VERSION ""

NS_ :

BS_:

BU_: MARVEL_3WL5_CAN_V0_3

BO_ 3221225472 VECTOR__INDEPENDENT_SIG_MSG: 0 Vector__XXX
 SG_ packVoltage_2949 : 0|8@0- (0.1,0) [0|0] "V" Vector__XXX
 SG_ pIn_OCD_WarningCurrent : 0|16@1+ (1,0) [0|0] "A" Vector__XXX
 SG_ pIn_OCD_ErrorCurrent : 0|16@1+ (1,0) [0|0] "A" Vector__XXX
 SG_ pIn_OTC_WarningTimeout : 0|16@1+ (1,0) [0|0] "ms" Vector__XXX
 SG_ pIn_OTC_ErrorTimeout : 0|16@1+ (1,0) [0|0] "ms" Vector__XXX
 SG_ pIn_OTC_RecoveryTimeout : 0|16@1+ (1,0) [0|0] "ms" Vector__XXX
 SG_ pIn_OTC_WarningTemperature : 0|8@1+ (1,0) [0|0] "C" Vector__XXX
 SG_ pIn_OTC_ErrorTemperature : 0|8@1+ (1,0) [0|0] "C" Vector__XXX
 SG_ pIn_OTC_RecoveryTemperature : 0|8@1+ (1,0) [0|0] "C" Vector__XXX
 SG_ pIn_OTD_WarningTemperature : 0|8@1+ (1,0) [0|0] "C" Vector__XXX
 SG_ pIn_OTD_ErrorTemperature : 0|8@1+ (1,0) [0|0] "C" Vector__XXX
 SG_ pIn_OTD_RecoveryTemperature : 0|8@1+ (1,0) [0|0] "C" Vector__XXX
 SG_ pIn_UTC_WarningTemperature : 0|8@1+ (1,0) [0|0] "C" Vector__XXX
 SG_ pIn_UTC_ErrorTemperature : 0|8@1+ (1,0) [0|0] "C" Vector__XXX
 SG_ pIn_UTC_RecoveryTemperature : 0|8@1+ (1,0) [0|0] "C" Vector__XXX
 SG_ pIn_UTD_WarningTemperature : 0|8@1+ (1,0) [0|0] "C" Vector__XXX
 SG_ pIn_UTD_ErrorTemperature : 0|8@1+ (1,0) [0|0] "C" Vector__XXX
 SG_ pIn_UTD_RecoveryTemperature : 0|8@1+ (1,0) [0|0] "C" Vector__XXX
 SG_ pIn_OV_RecoveryVoltage : 0|16@1+ (0.1,0) [0|0] "mV" Vector__XXX
 SG_ pIn_OV_ErrorVoltage : 0|16@1+ (0.1,0) [0|0] "mV" Vector__XXX
 SG_ pIn_OV_WarningVoltage : 0|16@1+ (0.1,0) [0|0] "mV" Vector__XXX
 SG_ pIn_UV_RecoveryVoltage : 0|16@1+ (0.1,0) [0|0] "mV" Vector__XXX
 SG_ pIn_UV_ErrorVoltage : 0|16@1+ (0.1,0) [0|0] "mV" Vector__XXX
 SG_ pIn_UV_WarningVoltage : 0|16@1+ (0.1,0) [0|0] "mV" Vector__XXX
 SG_ cbIn_BalMinThreshold : 0|16@1+ (0.1,0) [0|0] "mV" Vector__XXX
 SG_ cbIn_BalMaxAllowed_Imbalance : 0|16@1+ (0.1,0) [0|0] "mV" Vector__XXX
 SG_ cbIn_BalOVProtect_Threshold : 0|16@1+ (0.1,0) [0|0] "mV" Vector__XXX
 SG_ cbIn_BalStateRestPeriod : 0|16@1+ (1,0) [0|0] "ms" Vector__XXX
 SG_ Max_Allowed_Cell_Voltage : 0|16@1+ (1,0) [0|4150] "mV" Vector__XXX
 SG_ Max_Allowed_Pack_Voltage : 0|16@1+ (1,0) [0|83] "V" Vector__XXX
 SG_ Max_Allowed_Cell_Temperature : 0|16@1+ (1,0) [0|50] "C" Vector__XXX
 SG_ Max_Allowed_Current : 0|16@1+ (1,0) [0|200] "A" Vector__XXX
 SG_ Derated_Charge_Current : 0|16@1+ (0.1,0) [0|655.35] "A" Vector__XXX
 SG_ ccm_occ2Reg : 0|8@1+ (1,0) [0|0] "" Vector__XXX
 SG_ ccm_occ1Reg : 0|8@1+ (1,0) [0|0] "" Vector__XXX
 SG_ ccIn_VehicleRest_Time : 0|16@1+ (1,0) [0|0] "s" Vector__XXX
 SG_ ccIn_Max_CellCapacity : 0|16@1+ (1,0) [0|0] "Ah" Vector__XXX
 SG_ ccOut_Terminal_Voltage : 0|16@1+ (0.1,0) [0|0] "mV" Vector__XXX
 SG_ ccOut_EKF_Voltage : 0|16@1+ (0.1,0) [0|0] "mV" Vector__XXX
 SG_ ccOut_EKF_Capacity : 0|32@1- (1,0) [-2147483648|2147483647] "mAh" Vector__XXX
 SG_ ccOut_EKF_SOC_Pct : 0|8@1+ (1,0) [0|0] "" Vector__XXX
 SG_ Charging_State : 0|8@0+ (1,0) [0|1] "" Vector__XXX
 SG_ Charging_Current : 0|16@0+ (0.1,0) [0|180] "A" Vector__XXX
 SG_ Charging_Voltage : 0|16@0+ (0.1,0) [0|100] "V" Vector__XXX
 SG_ cIn_pOut_UTD : 0|8@1+ (1,0) [0|0] "" Vector__XXX
 SG_ cIn_pOut_UTC : 0|8@1+ (1,0) [0|0] "" Vector__XXX
 SG_ cIn_pOut_OTD : 0|8@1+ (1,0) [0|0] "" Vector__XXX
 SG_ cIn_pOut_OTC : 0|8@1+ (1,0) [0|0] "" Vector__XXX
 SG_ ErrorTypeGroup5 : 0|8@1- (1,0) [0|0] "" Vector__XXX
 SG_ ErrorTypeGroup4 : 0|8@1- (1,0) [0|0] "" Vector__XXX
 SG_ ErrorTypeGroup3 : 0|8@1- (1,0) [0|0] "" Vector__XXX
 SG_ TempGroup5 : 0|8@1- (1,0) [0|0] "" Vector__XXX
 SG_ TempGroup4 : 0|8@1- (1,0) [0|0] "" Vector__XXX
 SG_ TempGroup3 : 0|8@1- (1,0) [0|0] "" Vector__XXX
 SG_ pIn_Temp_20 : 0|8@1+ (1,0) [0|0] "C" Vector__XXX
 SG_ pIn_Temp_19 : 0|8@1+ (1,0) [0|0] "C" Vector__XXX
 SG_ pIn_Temp_18 : 0|8@1+ (1,0) [0|0] "C" Vector__XXX
 SG_ pIn_Temp_17 : 0|8@1+ (1,0) [0|0] "C" Vector__XXX
 SG_ pIn_Temp_16 : 0|8@1+ (1,0) [0|0] "C" Vector__XXX
 SG_ pIn_Temp_15 : 0|8@1+ (1,0) [0|0] "C" Vector__XXX
 SG_ Total_Cap_Remaining : 0|32@1- (1,0) [-2147483648|2147483647] "mAh" Vector__XXX
 SG_ Total_Cap_Charg_Discharge : 0|32@1- (1,0) [-2147483648|2147483647] "mAh" Vector__XXX
 SG_ Initial_Capacity : 0|32@1- (1,0) [-2147483648|2147483647] "mAh" Vector__XXX
 SG_ ccOut_CC_State : 0|8@1+ (1,0) [0|0] "" Vector__XXX
 SG_ ccOut_CC_SOC_Pct : 0|8@1+ (1,0) [0|0] "" Vector__XXX
 SG_ ccIn_Rest_Current : 0|8@1- (1,0) [0|0] "A" Vector__XXX
 SG_ ccIn_Voltage : 0|16@1+ (0.1,0) [0|0] "mV" Vector__XXX
 SG_ ccIn_pOut_OVThreshold : 0|8@1+ (1,0) [0|0] "" Vector__XXX
 SG_ ccIn_Current : 0|32@1- (0.01,0) [-1000|1000] "mA" Vector__XXX
 SG_ pIn_Temp_14 : 0|8@1+ (1,0) [0|0] "C" Vector__XXX
 SG_ CMU2_Cell_Voltage_12 : 0|16@1+ (0.1,0) [3100|4200] "mV" Vector__XXX
 SG_ CMU2_Cell_Voltage_11 : 0|16@1+ (0.1,0) [3100|4200] "mV" Vector__XXX
 SG_ CMU2_Cell_Voltage_10 : 0|16@1+ (0.1,0) [3100|4200] "mV" Vector__XXX
 SG_ CMU1_Cell_Voltage_12 : 0|16@1+ (0.1,0) [3100|4200] "mV" Vector__XXX
 SG_ CMU1_Cell_Voltage_11 : 0|16@1+ (0.1,0) [3100|4200] "mV" Vector__XXX
 SG_ CMU1_Cell_Voltage_10 : 0|16@1+ (0.1,0) [3100|4200] "mV" Vector__XXX
 SG_ errorDetect : 0|8@1- (1,0) [0|0] "" Vector__XXX
 SG_ eFuseFlag : 0|8@1- (1,0) [0|0] "" Vector__XXX
 SG_ dynamicCurrentState : 0|8@1- (1,0) [0|0] "" Vector__XXX
 SG_ errorDetect : 0|8@1- (1,0) [0|0] "" Vector__XXX

BO_ 831 calculatedFuseValue: 8 Vector__XXX
 SG_ i2t_Calculated_A2sec : 0|32@1- (1,0) [0|0] "" Vector__XXX

BO_ 263 ChargerID: 8 Vector__XXX
 SG_ ChargerCurrent : 23|16@0+ (0.1,0) [0|0] "Amps" Vector__XXX
 SG_ ChargerVoltage : 7|16@0+ (0.1,0) [0|0] "" Vector__XXX

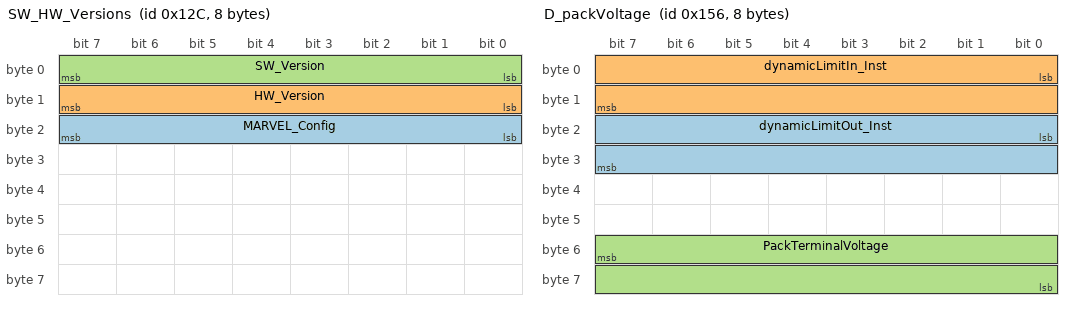
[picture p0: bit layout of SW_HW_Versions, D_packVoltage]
BO_ 300 SW_HW_Versions: 8 Vector__XXX
 SG_ MARVEL_Config : 16|8@1- (1,0) [0|0] "" Vector__XXX
 SG_ HW_Version : 8|8@1- (0.1,0) [0|0] "" Vector__XXX
 SG_ SW_Version : 0|8@1- (0.1,0) [0|0] "" Vector__XXX

BO_ 342 D_packVoltage: 8 Vector__XXX
 SG_ dynamicLimitOut_Inst : 16|16@1- (0.1,0) [0|0] "A" Vector__XXX
 SG_ dynamicLimitIn_Inst : 0|16@1- (0.1,0) [0|0] "" Vector__XXX
 SG_ PackTerminalVoltage : 55|16@0- (0.1,0) [0|0] "V" Vector__XXX

BO_ 801 AM_ccOutputs: 8 Vector__XXX
 SG_ TotalCapExchange : 32|32@1- (1,0) [0|0] "Ah" Vector__XXX
 SG_ MaxUsableCapacity : 0|32@1- (1,0) [0|0] "Ah" Vector__XXX

BO_ 829 DynamicCurrents: 8 Vector__XXX
 SG_ eFuseDischargingLimit_A2s : 32|32@1+ (1,0) [-1000000|1000000] "" Vector__XXX
 SG_ eFuseChargingLimit_A2s : 0|32@1+ (1,0) [-1000000|10000000] "" Vector__XXX

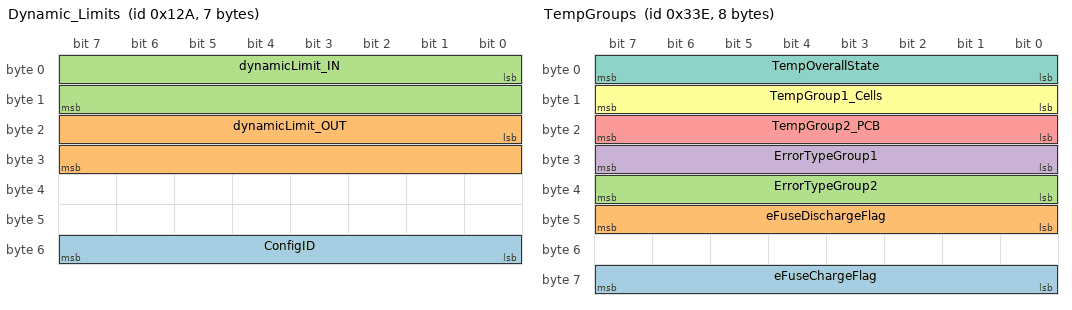
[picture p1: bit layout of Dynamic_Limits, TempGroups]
BO_ 298 Dynamic_Limits: 7 Vector__XXX
 SG_ ConfigID : 48|8@1- (1,0) [0|0] "" Vector__XXX
 SG_ dynamicLimit_OUT : 16|16@1- (0.1,0) [0|0] "A" Vector__XXX
 SG_ dynamicLimit_IN : 0|16@1- (0.1,0) [0|0] "A" Vector__XXX

BO_ 830 TempGroups: 8 Vector__XXX
 SG_ eFuseChargeFlag : 56|8@1- (1,0) [0|0] "" Vector__XXX
 SG_ eFuseDischargeFlag : 40|8@1- (1,0) [0|0] "" Vector__XXX
 SG_ ErrorTypeGroup2 : 32|8@1- (1,0) [0|0] "" Vector__XXX
 SG_ ErrorTypeGroup1 : 24|8@1- (1,0) [0|0] "" Vector__XXX
 SG_ TempGroup2_PCB : 16|8@1- (1,0) [0|0] "" Vector__XXX
 SG_ TempGroup1_Cells : 8|8@1- (1,0) [0|0] "" Vector__XXX
 SG_ TempOverallState : 0|8@1- (1,0) [0|0] "" Vector__XXX

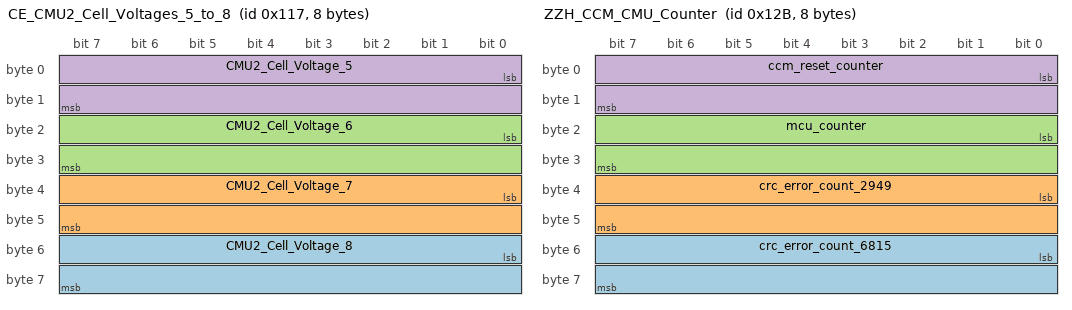
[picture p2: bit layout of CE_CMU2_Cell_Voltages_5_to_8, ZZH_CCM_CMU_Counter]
BO_ 279 CE_CMU2_Cell_Voltages_5_to_8: 8 Vector__XXX
 SG_ CMU2_Cell_Voltage_8 : 48|16@1+ (0.1,0) [3100|4200] "mV" Vector__XXX
 SG_ CMU2_Cell_Voltage_7 : 32|16@1+ (0.1,0) [3100|4200] "mV" Vector__XXX
 SG_ CMU2_Cell_Voltage_6 : 16|16@1+ (0.1,0) [3100|4200] "mV" Vector__XXX
 SG_ CMU2_Cell_Voltage_5 : 0|16@1+ (0.1,0) [3100|4200] "mV" Vector__XXX

BO_ 827 AL_ccOutput_Rem_Cap: 8 Vector__XXX
 SG_ TotalCapacityRemaining : 32|32@1- (1,0) [0|0] "mAh" Vector__XXX
 SG_ InitialCapacity : 0|32@1- (1,0) [0|0] "mAh" Vector__XXX

BO_ 299 ZZH_CCM_CMU_Counter: 8 Vector__XXX
 SG_ crc_error_count_6815 : 48|16@1+ (1,0) [0|0] "" Vector__XXX
 SG_ crc_error_count_2949 : 32|16@1+ (1,0) [0|0] "" Vector__XXX
 SG_ mcu_counter : 16|16@1+ (1,0) [0|0] "" Vector__XXX
 SG_ ccm_reset_counter : 0|16@1+ (1,0) [0|0] "" Vector__XXX

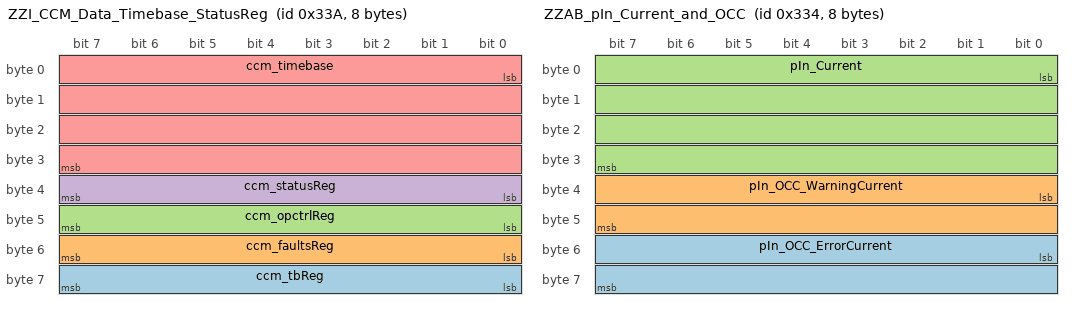
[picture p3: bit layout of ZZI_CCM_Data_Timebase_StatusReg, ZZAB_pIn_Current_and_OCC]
BO_ 826 ZZI_CCM_Data_Timebase_StatusReg: 8 Vector__XXX
 SG_ ccm_tbReg : 56|8@1+ (1,0) [0|0] "" Vector__XXX
 SG_ ccm_faultsReg : 48|8@1+ (1,0) [0|0] "" Vector__XXX
 SG_ ccm_opctrlReg : 40|8@1+ (1,0) [0|0] "" Vector__XXX
 SG_ ccm_statusReg : 32|8@1+ (1,0) [0|0] "" Vector__XXX
 SG_ ccm_timebase : 0|32@1+ (0.1,0) [0|429496729.5] "s" Vector__XXX

BO_ 820 ZZAB_pIn_Current_and_OCC: 8 Vector__XXX
 SG_ pIn_OCC_ErrorCurrent : 48|16@1+ (1,0) [0|0] "A" Vector__XXX
 SG_ pIn_OCC_WarningCurrent : 32|16@1+ (1,0) [0|0] "A" Vector__XXX
 SG_ pIn_Current : 0|32@1- (0.1,0) [-1000|1000] "mA" Vector__XXX

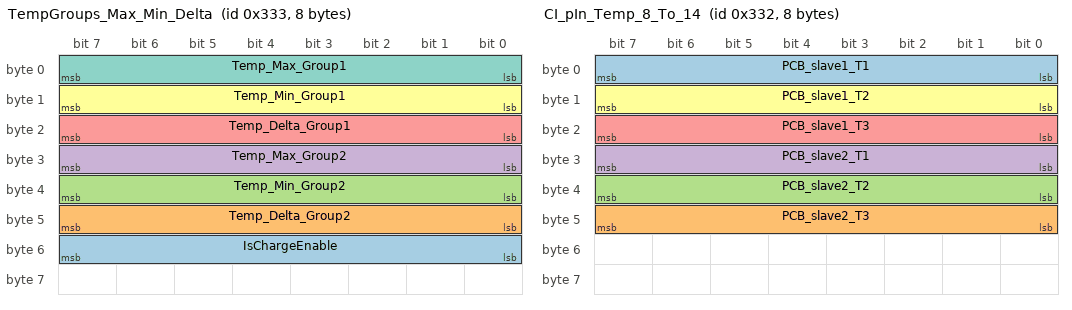
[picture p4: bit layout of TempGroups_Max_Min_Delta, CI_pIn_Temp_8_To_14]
BO_ 819 TempGroups_Max_Min_Delta: 8 Vector__XXX
 SG_ IsChargeEnable : 48|8@1+ (1,0) [0|0] "C" Vector__XXX
 SG_ Temp_Delta_Group2 : 40|8@1- (1,0) [0|0] "" Vector__XXX
 SG_ Temp_Min_Group2 : 32|8@1- (1,0) [0|0] "" Vector__XXX
 SG_ Temp_Max_Group2 : 24|8@1- (1,0) [0|0] "" Vector__XXX
 SG_ Temp_Delta_Group1 : 16|8@1+ (1,0) [0|0] "C" Vector__XXX
 SG_ Temp_Min_Group1 : 8|8@1+ (1,0) [0|0] "C" Vector__XXX
 SG_ Temp_Max_Group1 : 0|8@1+ (1,0) [0|0] "C" Vector__XXX

BO_ 818 CI_pIn_Temp_8_To_14: 8 Vector__XXX
 SG_ PCB_slave1_T1 : 0|8@1+ (1,0) [0|0] "C" Vector__XXX
 SG_ PCB_slave2_T3 : 40|8@1+ (1,0) [0|0] "C" Vector__XXX
 SG_ PCB_slave2_T2 : 32|8@1+ (1,0) [0|0] "C" Vector__XXX
 SG_ PCB_slave2_T1 : 24|8@1+ (1,0) [0|0] "C" Vector__XXX
 SG_ PCB_slave1_T3 : 16|8@1+ (1,0) [0|0] "C" Vector__XXX
 SG_ PCB_slave1_T2 : 8|8@1+ (1,0) [0|0] "C" Vector__XXX

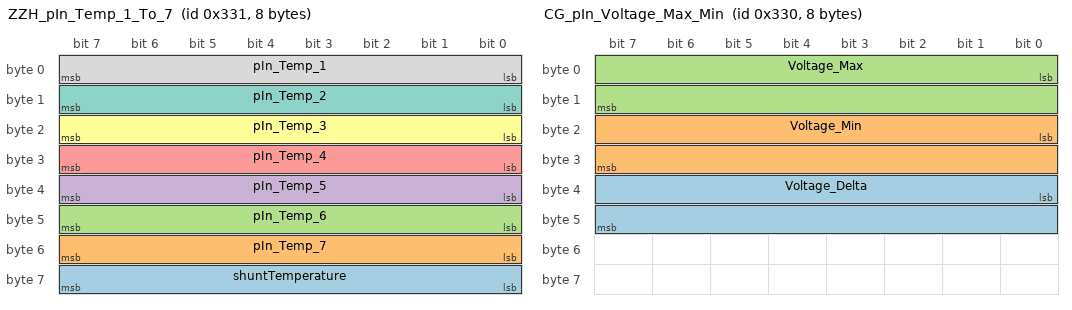
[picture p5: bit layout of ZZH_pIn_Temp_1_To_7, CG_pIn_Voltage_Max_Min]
BO_ 817 ZZH_pIn_Temp_1_To_7: 8 Vector__XXX
 SG_ shuntTemperature : 56|8@1- (1,0) [0|0] "deg" Vector__XXX
 SG_ pIn_Temp_7 : 48|8@1- (1,0) [0|0] "C" Vector__XXX
 SG_ pIn_Temp_6 : 40|8@1- (1,0) [0|0] "C" Vector__XXX
 SG_ pIn_Temp_5 : 32|8@1- (1,0) [0|0] "C" Vector__XXX
 SG_ pIn_Temp_4 : 24|8@1- (1,0) [0|0] "C" Vector__XXX
 SG_ pIn_Temp_3 : 16|8@1- (1,0) [0|0] "C" Vector__XXX
 SG_ pIn_Temp_2 : 8|8@1- (1,0) [0|0] "C" Vector__XXX
 SG_ pIn_Temp_1 : 0|8@1- (1,0) [0|0] "C" Vector__XXX

BO_ 816 CG_pIn_Voltage_Max_Min: 8 Vector__XXX
 SG_ Voltage_Delta : 32|16@1+ (0.1,0) [3100|4200] "mV" Vector__XXX
 SG_ Voltage_Min : 16|16@1+ (0.1,0) [3100|4200] "mV" Vector__XXX
 SG_ Voltage_Max : 0|16@1+ (0.1,0) [3100|4200] "mV" Vector__XXX

BO_ 280 CF_CMU2_Cell_Voltages_9_to_12: 8 Vector__XXX
 SG_ CMU2_Cell_Voltage_9 : 0|16@1+ (0.1,0) [3100|4200] "mV" Vector__XXX

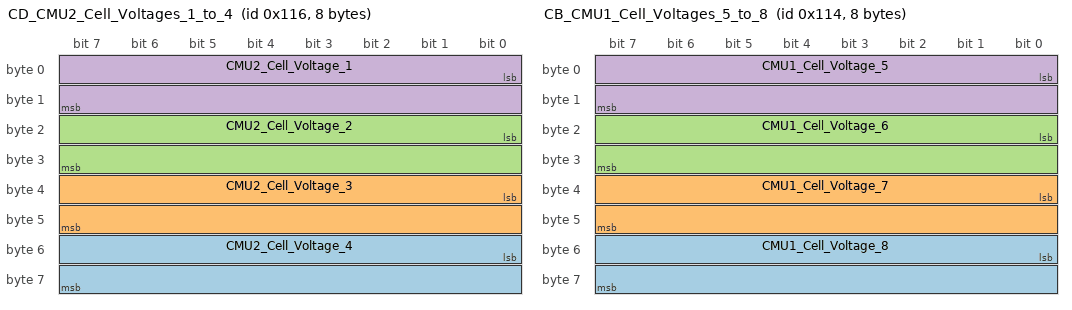
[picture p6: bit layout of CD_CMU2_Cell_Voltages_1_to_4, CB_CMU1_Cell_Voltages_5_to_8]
BO_ 278 CD_CMU2_Cell_Voltages_1_to_4: 8 Vector__XXX
 SG_ CMU2_Cell_Voltage_4 : 48|16@1+ (0.1,0) [3100|4200] "mV" Vector__XXX
 SG_ CMU2_Cell_Voltage_3 : 32|16@1+ (0.1,0) [3100|4200] "mV" Vector__XXX
 SG_ CMU2_Cell_Voltage_2 : 16|16@1+ (0.1,0) [3100|4200] "mV" Vector__XXX
 SG_ CMU2_Cell_Voltage_1 : 0|16@1+ (0.1,0) [3100|4200] "mV" Vector__XXX

BO_ 277 CC_CMU1_Cell_Voltages_9_to_12: 8 Vector__XXX
 SG_ CMU1_Cell_Voltage_9 : 0|16@1+ (0.1,0) [3100|4200] "mV" Vector__XXX

BO_ 276 CB_CMU1_Cell_Voltages_5_to_8: 8 Vector__XXX
 SG_ CMU1_Cell_Voltage_8 : 48|16@1+ (0.1,0) [3100|4200] "mV" Vector__XXX
 SG_ CMU1_Cell_Voltage_7 : 32|16@1+ (0.1,0) [3100|4200] "mV" Vector__XXX
 SG_ CMU1_Cell_Voltage_6 : 16|16@1+ (0.1,0) [3100|4200] "mV" Vector__XXX
 SG_ CMU1_Cell_Voltage_5 : 0|16@1+ (0.1,0) [3100|4200] "mV" Vector__XXX

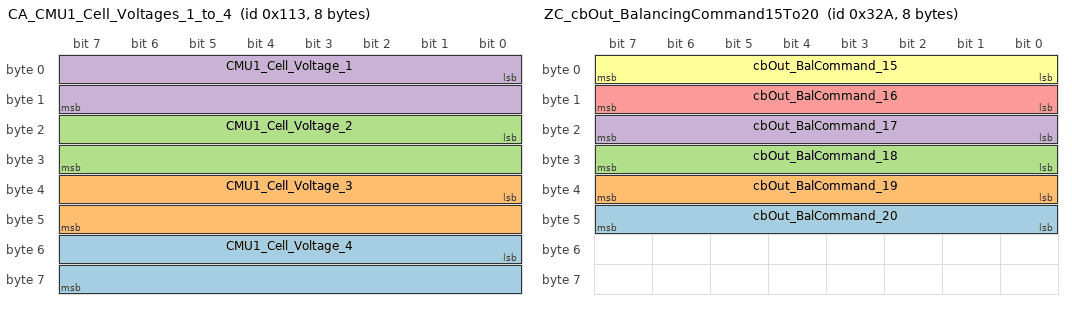
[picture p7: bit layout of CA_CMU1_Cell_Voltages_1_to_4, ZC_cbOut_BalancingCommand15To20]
BO_ 275 CA_CMU1_Cell_Voltages_1_to_4: 8 Vector__XXX
 SG_ CMU1_Cell_Voltage_4 : 48|16@1+ (0.1,0) [3100|4200] "mV" Vector__XXX
 SG_ CMU1_Cell_Voltage_3 : 32|16@1+ (0.1,0) [3100|4200] "mV" Vector__XXX
 SG_ CMU1_Cell_Voltage_2 : 16|16@1+ (0.1,0) [3100|4200] "mV" Vector__XXX
 SG_ CMU1_Cell_Voltage_1 : 0|16@1+ (0.1,0) [3100|4200] "mV" Vector__XXX

BO_ 810 ZC_cbOut_BalancingCommand15To20: 8 Vector__XXX
 SG_ cbOut_BalCommand_20 : 40|8@1+ (1,0) [0|0] "" Vector__XXX
 SG_ cbOut_BalCommand_19 : 32|8@1+ (1,0) [0|0] "" Vector__XXX
 SG_ cbOut_BalCommand_18 : 24|8@1+ (1,0) [0|0] "" Vector__XXX
 SG_ cbOut_BalCommand_17 : 16|8@1+ (1,0) [0|0] "" Vector__XXX
 SG_ cbOut_BalCommand_16 : 8|8@1+ (1,0) [0|0] "" Vector__XXX
 SG_ cbOut_BalCommand_15 : 0|8@1+ (1,0) [0|0] "" Vector__XXX

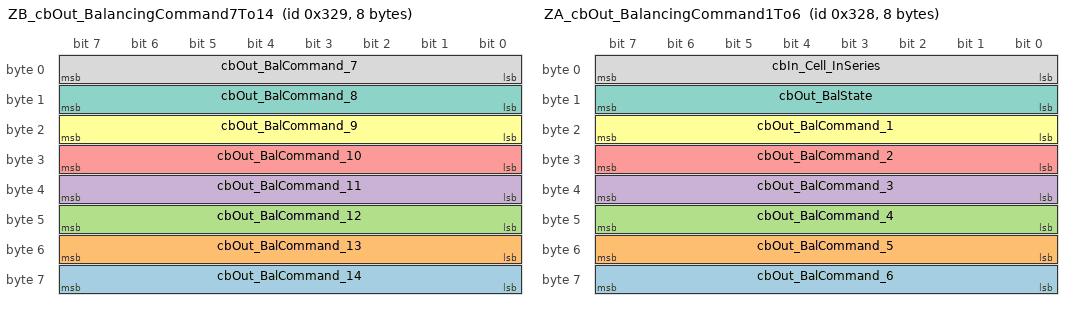
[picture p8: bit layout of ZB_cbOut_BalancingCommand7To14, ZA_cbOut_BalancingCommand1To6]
BO_ 809 ZB_cbOut_BalancingCommand7To14: 8 Vector__XXX
 SG_ cbOut_BalCommand_14 : 56|8@1+ (1,0) [0|0] "" Vector__XXX
 SG_ cbOut_BalCommand_13 : 48|8@1+ (1,0) [0|0] "" Vector__XXX
 SG_ cbOut_BalCommand_12 : 40|8@1+ (1,0) [0|0] "" Vector__XXX
 SG_ cbOut_BalCommand_11 : 32|8@1+ (1,0) [0|0] "" Vector__XXX
 SG_ cbOut_BalCommand_10 : 24|8@1+ (1,0) [0|0] "" Vector__XXX
 SG_ cbOut_BalCommand_9 : 16|8@1+ (1,0) [0|0] "" Vector__XXX
 SG_ cbOut_BalCommand_8 : 8|8@1+ (1,0) [0|0] "" Vector__XXX
 SG_ cbOut_BalCommand_7 : 0|8@1+ (1,0) [0|0] "" Vector__XXX

BO_ 808 ZA_cbOut_BalancingCommand1To6: 8 Vector__XXX
 SG_ cbOut_BalCommand_6 : 56|8@1+ (1,0) [0|0] "" Vector__XXX
 SG_ cbOut_BalCommand_5 : 48|8@1+ (1,0) [0|0] "" Vector__XXX
 SG_ cbOut_BalCommand_4 : 40|8@1+ (1,0) [0|0] "" Vector__XXX
 SG_ cbOut_BalCommand_3 : 32|8@1+ (1,0) [0|0] "" Vector__XXX
 SG_ cbOut_BalCommand_2 : 24|8@1+ (1,0) [0|0] "" Vector__XXX
 SG_ cbOut_BalCommand_1 : 16|8@1+ (1,0) [0|0] "" Vector__XXX
 SG_ cbOut_BalState : 8|8@1+ (1,0) [0|0] "" Vector__XXX
 SG_ cbIn_Cell_InSeries : 0|8@1+ (1,0) [0|0] "" Vector__XXX

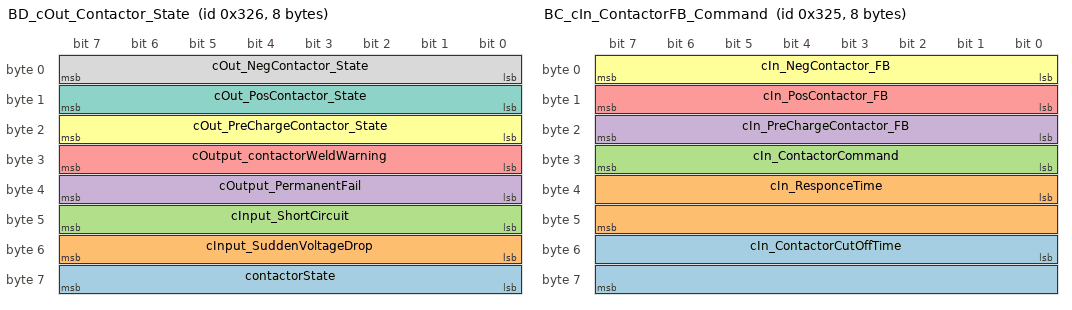
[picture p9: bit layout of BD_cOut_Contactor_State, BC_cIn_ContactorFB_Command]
BO_ 806 BD_cOut_Contactor_State: 8 Vector__XXX
 SG_ contactorState : 56|8@1- (1,0) [0|0] "" Vector__XXX
 SG_ cInput_SuddenVoltageDrop : 48|8@1- (1,0) [0|0] "" Vector__XXX
 SG_ cInput_ShortCircuit : 40|8@1- (1,0) [0|0] "" Vector__XXX
 SG_ cOutput_PermanentFail : 32|8@1- (1,0) [0|0] "" Vector__XXX
 SG_ cOutput_contactorWeldWarning : 24|8@1- (1,0) [0|0] "" Vector__XXX
 SG_ cOut_PreChargeContactor_State : 16|8@1+ (1,0) [0|0] "" Vector__XXX
 SG_ cOut_PosContactor_State : 8|8@1+ (1,0) [0|0] "" Vector__XXX
 SG_ cOut_NegContactor_State : 0|8@1+ (1,0) [0|0] "" Vector__XXX

BO_ 805 BC_cIn_ContactorFB_Command: 8 Vector__XXX
 SG_ cIn_ContactorCutOffTime : 48|16@1+ (1,0) [0|0] "ms" Vector__XXX
 SG_ cIn_ResponceTime : 32|16@1+ (1,0) [0|0] "ms" Vector__XXX
 SG_ cIn_ContactorCommand : 24|8@1+ (1,0) [0|0] "" Vector__XXX
 SG_ cIn_PreChargeContactor_FB : 16|8@1+ (1,0) [0|0] "" Vector__XXX
 SG_ cIn_PosContactor_FB : 8|8@1+ (1,0) [0|0] "" Vector__XXX
 SG_ cIn_NegContactor_FB : 0|8@1+ (1,0) [0|0] "" Vector__XXX

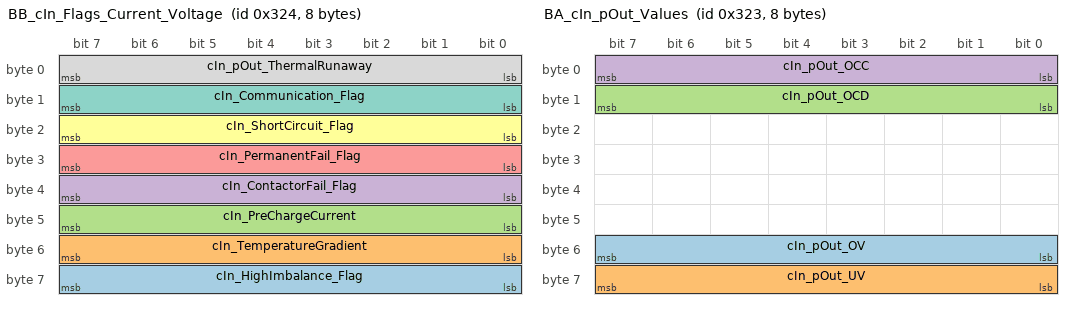
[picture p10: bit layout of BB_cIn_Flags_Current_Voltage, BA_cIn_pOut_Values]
BO_ 804 BB_cIn_Flags_Current_Voltage: 8 Vector__XXX
 SG_ cIn_HighImbalance_Flag : 56|8@1+ (1,0) [0|0] "" Vector__XXX
 SG_ cIn_TemperatureGradient : 48|8@1+ (1,0) [0|0] "" Vector__XXX
 SG_ cIn_PreChargeCurrent : 40|8@1+ (1,0) [0|0] "mA" Vector__XXX
 SG_ cIn_ContactorFail_Flag : 32|8@1+ (1,0) [0|0] "" Vector__XXX
 SG_ cIn_PermanentFail_Flag : 24|8@1+ (1,0) [0|0] "" Vector__XXX
 SG_ cIn_ShortCircuit_Flag : 16|8@1+ (1,0) [0|0] "" Vector__XXX
 SG_ cIn_Communication_Flag : 8|8@1+ (1,0) [0|0] "" Vector__XXX
 SG_ cIn_pOut_ThermalRunaway : 0|8@1+ (1,0) [0|0] "" Vector__XXX

BO_ 803 BA_cIn_pOut_Values: 8 Vector__XXX
 SG_ cIn_pOut_OV : 48|8@1+ (1,0) [0|0] "" Vector__XXX
 SG_ cIn_pOut_UV : 56|8@1+ (1,0) [0|0] "" Vector__XXX
 SG_ cIn_pOut_OCD : 8|8@1+ (1,0) [0|0] "" Vector__XXX
 SG_ cIn_pOut_OCC : 0|8@1+ (1,0) [0|0] "" Vector__XXX

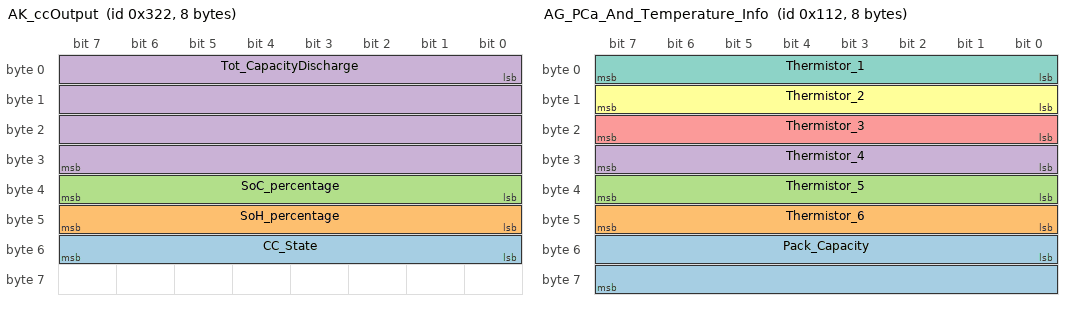
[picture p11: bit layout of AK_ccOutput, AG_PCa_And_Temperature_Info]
BO_ 802 AK_ccOutput: 8 Vector__XXX
 SG_ CC_State : 48|8@1- (1,0) [0|0] "" Vector__XXX
 SG_ SoH_percentage : 40|8@1+ (1,0) [0|0] "%" Vector__XXX
 SG_ SoC_percentage : 32|8@1+ (1,0) [0|0] "%" Vector__XXX
 SG_ Tot_CapacityDischarge : 0|32@1- (1,0) [0|0] "mAh" Vector__XXX

BO_ 274 AG_PCa_And_Temperature_Info: 8 MARVEL_3WL5_CAN_V0_3
 SG_ Pack_Capacity : 48|16@1+ (0.1,0) [0|1000000] "Ah" Vector__XXX
 SG_ Thermistor_6 : 40|8@1+ (1,0) [0|255] "C" Vector__XXX
 SG_ Thermistor_5 : 32|8@1+ (1,0) [0|255] "C" Vector__XXX
 SG_ Thermistor_4 : 24|8@1+ (1,0) [0|255] "C" Vector__XXX
 SG_ Thermistor_3 : 16|8@1+ (1,0) [0|255] "C" Vector__XXX
 SG_ Thermistor_2 : 8|8@1+ (1,0) [0|255] "C" Vector__XXX
 SG_ Thermistor_1 : 0|8@1+ (1,0) [0|255] "C" Vector__XXX

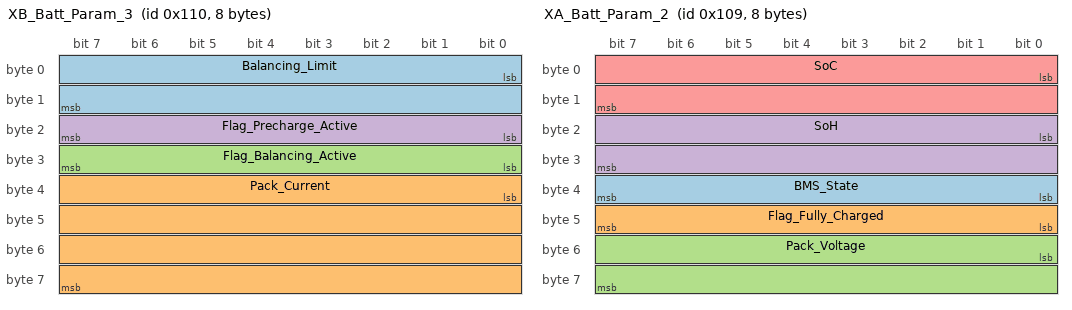
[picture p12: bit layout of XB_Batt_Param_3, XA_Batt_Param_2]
BO_ 272 XB_Batt_Param_3: 8 MARVEL_3WL5_CAN_V0_3
 SG_ Balancing_Limit : 0|16@1+ (0.1,0) [0|4200] "mV" Vector__XXX
 SG_ Pack_Current : 32|32@1- (1E-005,0) [-1000|1000] "A" Vector__XXX
 SG_ Flag_Balancing_Active : 24|8@1+ (1,0) [0|1] "" Vector__XXX
 SG_ Flag_Precharge_Active : 16|8@1+ (1,0) [0|1] "" Vector__XXX

BO_ 265 XA_Batt_Param_2: 8 MARVEL_3WL5_CAN_V0_3
 SG_ BMS_State : 32|8@1+ (1,0) [0|5] "" Vector__XXX
 SG_ Flag_Fully_Charged : 40|8@1+ (1,0) [0|1] "" Vector__XXX
 SG_ Pack_Voltage : 48|16@1+ (0.1,0) [60|85] "V" Vector__XXX
 SG_ SoH : 16|16@1+ (0.01,0) [0|100] "%" Vector__XXX
 SG_ SoC : 0|16@1+ (0.01,0) [0|100] "%" Vector__XXX

CM_ BO_ 3221225472 "This is a message for not used signals, created by Vector CANdb++ DBC OLE DB Provider.";
CM_ BO_ 274 "PCa - Pack Capacity, And Temperatures.
1-4 are external NTC 1-4 of slave one
5-6 are external NTC 1-2 of slave two";
BA_DEF_  "BusType" STRING ;
BA_DEF_DEF_  "BusType" "CAN";
